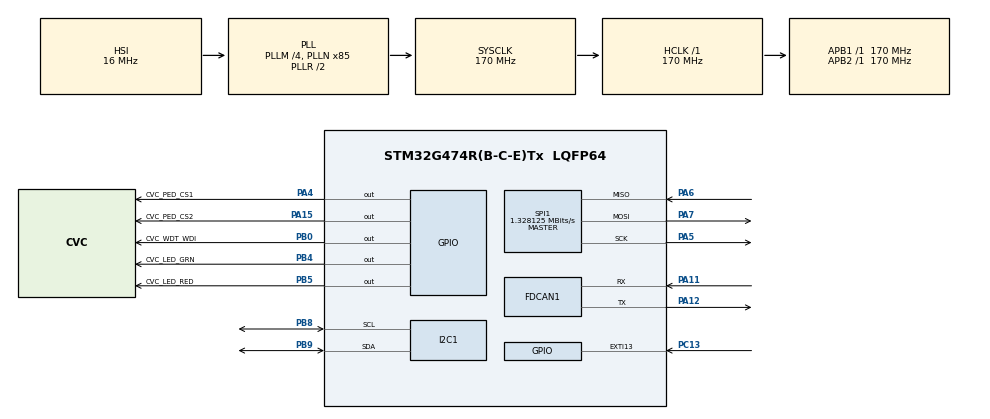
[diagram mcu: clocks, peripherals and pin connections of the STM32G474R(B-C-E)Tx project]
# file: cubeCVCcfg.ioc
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FDCAN1.AutoRetransmission=ENABLE
FDCAN1.CalculateBaudRateNominal=500000
FDCAN1.CalculateTimeBitNominal=2000
FDCAN1.CalculateTimeQuantumNominal=100.0
FDCAN1.NominalPrescaler=17
FDCAN1.NominalTimeSeg1=15
FDCAN1.NominalTimeSeg2=4
FDCAN1.StdFiltersNbr=4
I2C1.Timing=0x40B285C2
Mcu.Family=STM32G4
Mcu.Name=STM32G474R(B-C-E)Tx
Mcu.Package=LQFP64
NUCLEO-G474RE.BUTTON=1
NUCLEO-G474RE.Bsp_Common_DEMO=true
NVIC.EXTI15_10_IRQn=true\:0\:0\:false\:false\:true\:false\:true\:true
NVIC.PriorityGroup=NVIC_PRIORITYGROUP_4
PA11.Mode=FDCAN_Activate
PA11.Signal=FDCAN1_RX
PA12.Mode=FDCAN_Activate
PA12.Signal=FDCAN1_TX
PA13.GPIO_Label=T_SWDIO
PA13.Mode=Serial_Wire
PA13.Signal=SYS_JTMS-SWDIO
PA14.GPIO_Label=T_SWCLK
PA14.Mode=Serial_Wire
PA14.Signal=SYS_JTCK-SWCLK
PA15.GPIO_Label=CVC_PED_CS2
PA15.PinState=GPIO_PIN_SET
PA15.Signal=GPIO_Output
PA4.GPIO_Label=CVC_PED_CS1
PA4.PinState=GPIO_PIN_SET
PA4.Signal=GPIO_Output
PA5.Mode=Full_Duplex_Master
PA5.Signal=SPI1_SCK
PA6.Mode=Full_Duplex_Master
PA6.Signal=SPI1_MISO
PA7.Mode=Full_Duplex_Master
PA7.Signal=SPI1_MOSI
PB0.GPIO_Label=CVC_WDT_WDI
PB0.Signal=GPIO_Output
PB4.GPIO_Label=CVC_LED_GRN
PB4.Signal=GPIO_Output
PB5.GPIO_Label=CVC_LED_RED
PB5.Signal=GPIO_Output
PB8-BOOT0.Mode=I2C
PB8-BOOT0.Signal=I2C1_SCL
PB9.Mode=I2C
PB9.Signal=I2C1_SDA
PC13.Signal=GPXTI13
PC14-OSC32_IN.GPIO_Label=RCC_OSC32_IN
PC14-OSC32_IN.Signal=RCC_OSC32_IN
PC15-OSC32_OUT.GPIO_Label=RCC_OSC32_OUT
PC15-OSC32_OUT.Signal=RCC_OSC32_OUT
PF0-OSC_IN.GPIO_Label=RCC_OSC_IN
PF0-OSC_IN.Signal=RCC_OSC_IN
PF1-OSC_OUT.GPIO_Label=RCC_OSC_OUT
PF1-OSC_OUT.Signal=RCC_OSC_OUT
ProjectManager.HeapSize=0x200
ProjectManager.StackSize=0x400
ProjectManager.TargetToolchain=Makefile
RCC.ADC12Freq_Value=170000000
RCC.ADC345Freq_Value=170000000
RCC.AHBFreq_Value=170000000
RCC.APB1Freq_Value=170000000
RCC.APB1TimFreq_Value=170000000
RCC.APB2Freq_Value=170000000
RCC.APB2TimFreq_Value=170000000
RCC.CortexFreq_Value=170000000
RCC.EXTERNAL_CLOCK_VALUE=12288000
RCC.HCLKFreq_Value=170000000
RCC.HSE_VALUE=24000000
RCC.HSI48_VALUE=48000000
RCC.HSI_VALUE=16000000
RCC.LSE_VALUE=32768
RCC.PLLM=RCC_PLLM_DIV4
RCC.PLLN=85
RCC.RTCClockSelection=RCC_RTCCLKSOURCE_LSE
RCC.SYSCLKFreq_VALUE=170000000
RCC.SYSCLKSource=RCC_SYSCLKSOURCE_PLLCLK
RCC.USBFreq_Value=170000000
RCC.VCOOutputFreq_Value=340000000
SPI1.BaudRatePrescaler=SPI_BAUDRATEPRESCALER_128
SPI1.CLKPhase=SPI_PHASE_2EDGE
SPI1.CalculateBaudRate=1.328125 MBits/s
SPI1.DataSize=SPI_DATASIZE_16BIT
SPI1.Direction=SPI_DIRECTION_2LINES
SPI1.Mode=SPI_MODE_MASTER
SPI1.VirtualType=VM_MASTER
VP_NUCLEO-G474RE_VS_BSP_COMMON.Mode=COMMON
VP_SYS_VS_DBSignals.Mode=DisableDeadBatterySignals
board=NUCLEO-G474RE

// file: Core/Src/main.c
/* USER CODE BEGIN Header */
/**
  ******************************************************************************
  * @file           : main.c
  * @brief          : Main program body
  ******************************************************************************
  * @attention
  *
  * Copyright (c) 2026 STMicroelectronics.
  * All rights reserved.
  *
  * This software is licensed under terms that can be found in the LICENSE file
  * in the root directory of this software component.
  * If no LICENSE file comes with this software, it is provided AS-IS.
  *
  ******************************************************************************
  */
/* USER CODE END Header */
#include "main.h"

__IO uint32_t BspButtonState = BUTTON_RELEASED;
FDCAN_HandleTypeDef hfdcan1;

I2C_HandleTypeDef hi2c1;

SPI_HandleTypeDef hspi1;

void SystemClock_Config(void);
static void MX_GPIO_Init(void);
static void MX_FDCAN1_Init(void);
static void MX_I2C1_Init(void);
static void MX_SPI1_Init(void);

int main(void)
{

  /* MCU Configuration--------------------------------------------------------*/

  /* Reset of all peripherals, Initializes the Flash interface and the Systick. */
  HAL_Init();

  /* Configure the system clock */
  SystemClock_Config();

  /* Initialize all configured peripherals */
  MX_GPIO_Init();
  MX_FDCAN1_Init();
  MX_I2C1_Init();
  MX_SPI1_Init();

  /* Initialize USER push-button, will be used to trigger an interrupt each time it's pressed.*/
  BSP_PB_Init(BUTTON_USER, BUTTON_MODE_EXTI);

  /* Infinite loop */
  /* USER CODE BEGIN WHILE */
  while (1)
  {

    /* -- Sample board code for User push-button in interrupt mode ---- */
    if (BspButtonState == BUTTON_PRESSED)
    {
      /* Update button state */
      BspButtonState = BUTTON_RELEASED;
      /* ..... Perform your action ..... */
    }
    /* USER CODE END WHILE */

  }
}

void SystemClock_Config(void)
{
  RCC_OscInitTypeDef RCC_OscInitStruct = {0};
  RCC_ClkInitTypeDef RCC_ClkInitStruct = {0};

  /** Configure the main internal regulator output voltage
  */
  HAL_PWREx_ControlVoltageScaling(PWR_REGULATOR_VOLTAGE_SCALE1_BOOST);

  /** Initializes the RCC Oscillators according to the specified parameters
  * in the RCC_OscInitTypeDef structure.
  */
  RCC_OscInitStruct.OscillatorType = RCC_OSCILLATORTYPE_HSI;
  RCC_OscInitStruct.HSIState = RCC_HSI_ON;
  RCC_OscInitStruct.HSICalibrationValue = RCC_HSICALIBRATION_DEFAULT;
  RCC_OscInitStruct.PLL.PLLState = RCC_PLL_ON;
  RCC_OscInitStruct.PLL.PLLSource = RCC_PLLSOURCE_HSI;
  RCC_OscInitStruct.PLL.PLLM = RCC_PLLM_DIV4;
  RCC_OscInitStruct.PLL.PLLN = 85;
  RCC_OscInitStruct.PLL.PLLP = RCC_PLLP_DIV2;
  RCC_OscInitStruct.PLL.PLLQ = RCC_PLLQ_DIV2;
  RCC_OscInitStruct.PLL.PLLR = RCC_PLLR_DIV2;
  if (HAL_RCC_OscConfig(&RCC_OscInitStruct) != HAL_OK)
  {
    Error_Handler();
  }

  /** Initializes the CPU, AHB and APB buses clocks
  */
  RCC_ClkInitStruct.ClockType = RCC_CLOCKTYPE_HCLK|RCC_CLOCKTYPE_SYSCLK
                              |RCC_CLOCKTYPE_PCLK1|RCC_CLOCKTYPE_PCLK2;
  RCC_ClkInitStruct.SYSCLKSource = RCC_SYSCLKSOURCE_PLLCLK;
  RCC_ClkInitStruct.AHBCLKDivider = RCC_SYSCLK_DIV1;
  RCC_ClkInitStruct.APB1CLKDivider = RCC_HCLK_DIV1;
  RCC_ClkInitStruct.APB2CLKDivider = RCC_HCLK_DIV1;

  if (HAL_RCC_ClockConfig(&RCC_ClkInitStruct, FLASH_LATENCY_4) != HAL_OK)
  {
    Error_Handler();
  }
}

static void MX_FDCAN1_Init(void)
{

  hfdcan1.Instance = FDCAN1;
  hfdcan1.Init.ClockDivider = FDCAN_CLOCK_DIV1;
  hfdcan1.Init.FrameFormat = FDCAN_FRAME_CLASSIC;
  hfdcan1.Init.Mode = FDCAN_MODE_NORMAL;
  hfdcan1.Init.AutoRetransmission = ENABLE;
  hfdcan1.Init.TransmitPause = DISABLE;
  hfdcan1.Init.ProtocolException = DISABLE;
  hfdcan1.Init.NominalPrescaler = 17;
  hfdcan1.Init.NominalSyncJumpWidth = 1;
  hfdcan1.Init.NominalTimeSeg1 = 15;
  hfdcan1.Init.NominalTimeSeg2 = 4;
  hfdcan1.Init.DataPrescaler = 1;
  hfdcan1.Init.DataSyncJumpWidth = 1;
  hfdcan1.Init.DataTimeSeg1 = 1;
  hfdcan1.Init.DataTimeSeg2 = 1;
  hfdcan1.Init.StdFiltersNbr = 4;
  hfdcan1.Init.ExtFiltersNbr = 0;
  hfdcan1.Init.TxFifoQueueMode = FDCAN_TX_FIFO_OPERATION;
  if (HAL_FDCAN_Init(&hfdcan1) != HAL_OK)
  {
    Error_Handler();
  }

}

static void MX_I2C1_Init(void)
{

  hi2c1.Instance = I2C1;
  hi2c1.Init.Timing = 0x40B285C2;
  hi2c1.Init.OwnAddress1 = 0;
  hi2c1.Init.AddressingMode = I2C_ADDRESSINGMODE_7BIT;
  hi2c1.Init.DualAddressMode = I2C_DUALADDRESS_DISABLE;
  hi2c1.Init.OwnAddress2 = 0;
  hi2c1.Init.OwnAddress2Masks = I2C_OA2_NOMASK;
  hi2c1.Init.GeneralCallMode = I2C_GENERALCALL_DISABLE;
  hi2c1.Init.NoStretchMode = I2C_NOSTRETCH_DISABLE;
  if (HAL_I2C_Init(&hi2c1) != HAL_OK)
  {
    Error_Handler();
  }

  /** Configure Analogue filter
  */
  if (HAL_I2CEx_ConfigAnalogFilter(&hi2c1, I2C_ANALOGFILTER_ENABLE) != HAL_OK)
  {
    Error_Handler();
  }

  /** Configure Digital filter
  */
  if (HAL_I2CEx_ConfigDigitalFilter(&hi2c1, 0) != HAL_OK)
  {
    Error_Handler();
  }

}

static void MX_SPI1_Init(void)
{

  /* SPI1 parameter configuration*/
  hspi1.Instance = SPI1;
  hspi1.Init.Mode = SPI_MODE_MASTER;
  hspi1.Init.Direction = SPI_DIRECTION_2LINES;
  hspi1.Init.DataSize = SPI_DATASIZE_16BIT;
  hspi1.Init.CLKPolarity = SPI_POLARITY_LOW;
  hspi1.Init.CLKPhase = SPI_PHASE_2EDGE;
  hspi1.Init.NSS = SPI_NSS_SOFT;
  hspi1.Init.BaudRatePrescaler = SPI_BAUDRATEPRESCALER_128;
  hspi1.Init.FirstBit = SPI_FIRSTBIT_MSB;
  hspi1.Init.TIMode = SPI_TIMODE_DISABLE;
  hspi1.Init.CRCCalculation = SPI_CRCCALCULATION_DISABLE;
  hspi1.Init.CRCPolynomial = 7;
  hspi1.Init.CRCLength = SPI_CRC_LENGTH_DATASIZE;
  hspi1.Init.NSSPMode = SPI_NSS_PULSE_DISABLE;
  if (HAL_SPI_Init(&hspi1) != HAL_OK)
  {
    Error_Handler();
  }

}

static void MX_GPIO_Init(void)
{
  GPIO_InitTypeDef GPIO_InitStruct = {0};

  /* GPIO Ports Clock Enable */
  __HAL_RCC_GPIOC_CLK_ENABLE();
  __HAL_RCC_GPIOF_CLK_ENABLE();
  __HAL_RCC_GPIOA_CLK_ENABLE();
  __HAL_RCC_GPIOB_CLK_ENABLE();

  /*Configure GPIO pin Output Level */
  HAL_GPIO_WritePin(GPIOA, CVC_PED_CS1_Pin|CVC_PED_CS2_Pin, GPIO_PIN_SET);

  /*Configure GPIO pin Output Level */
  HAL_GPIO_WritePin(GPIOB, CVC_WDT_WDI_Pin|CVC_LED_GRN_Pin|CVC_LED_RED_Pin, GPIO_PIN_RESET);

  /*Configure GPIO pins : CVC_PED_CS1_Pin CVC_PED_CS2_Pin */
  GPIO_InitStruct.Pin = CVC_PED_CS1_Pin|CVC_PED_CS2_Pin;
  GPIO_InitStruct.Mode = GPIO_MODE_OUTPUT_PP;
  GPIO_InitStruct.Pull = GPIO_NOPULL;
  GPIO_InitStruct.Speed = GPIO_SPEED_FREQ_LOW;
  HAL_GPIO_Init(GPIOA, &GPIO_InitStruct);

  /*Configure GPIO pins : CVC_WDT_WDI_Pin CVC_LED_GRN_Pin CVC_LED_RED_Pin */
  GPIO_InitStruct.Pin = CVC_WDT_WDI_Pin|CVC_LED_GRN_Pin|CVC_LED_RED_Pin;
  GPIO_InitStruct.Mode = GPIO_MODE_OUTPUT_PP;
  GPIO_InitStruct.Pull = GPIO_NOPULL;
  GPIO_InitStruct.Speed = GPIO_SPEED_FREQ_LOW;
  HAL_GPIO_Init(GPIOB, &GPIO_InitStruct);

}

/**
  * @brief BSP Push Button callback
  * @param Button Specifies the pressed button
  * @retval None
  */
void BSP_PB_Callback(Button_TypeDef Button)
{
  if (Button == BUTTON_USER)
  {
    BspButtonState = BUTTON_PRESSED;
  }
}

void Error_Handler(void)
{
  __disable_irq();
  while (1)
  {
  }
}
